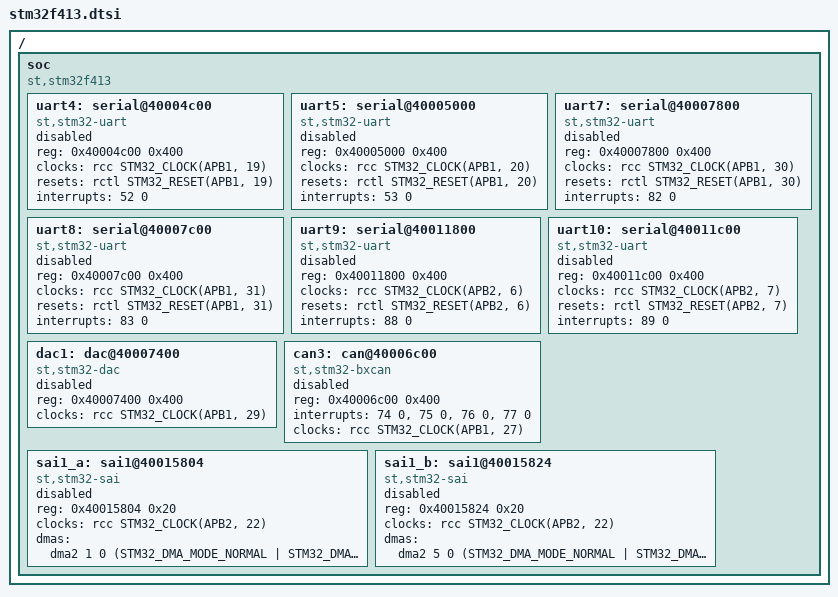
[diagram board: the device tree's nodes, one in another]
/*
 * Copyright (c) 2017 Florian Vaussard, HEIG-VD
 * Copyright (c) 2025 Mario Paja
 *
 * SPDX-License-Identifier: Apache-2.0
 */

#include <st/f4/stm32f412.dtsi>

/ {
	soc {
		compatible = "st,stm32f413", "st,stm32f4", "simple-bus";

		uart4: serial@40004c00 {
			compatible = "st,stm32-uart";
			reg = <0x40004c00 0x400>;
			clocks = <&rcc STM32_CLOCK(APB1, 19)>;
			resets = <&rctl STM32_RESET(APB1, 19)>;
			interrupts = <52 0>;
			status = "disabled";
		};

		uart5: serial@40005000 {
			compatible = "st,stm32-uart";
			reg = <0x40005000 0x400>;
			clocks = <&rcc STM32_CLOCK(APB1, 20)>;
			resets = <&rctl STM32_RESET(APB1, 20)>;
			interrupts = <53 0>;
			status = "disabled";
		};

		uart7: serial@40007800 {
			compatible = "st,stm32-uart";
			reg = <0x40007800 0x400>;
			clocks = <&rcc STM32_CLOCK(APB1, 30)>;
			resets = <&rctl STM32_RESET(APB1, 30)>;
			interrupts = <82 0>;
			status = "disabled";
		};

		uart8: serial@40007c00 {
			compatible = "st,stm32-uart";
			reg = <0x40007c00 0x400>;
			clocks = <&rcc STM32_CLOCK(APB1, 31)>;
			resets = <&rctl STM32_RESET(APB1, 31)>;
			interrupts = <83 0>;
			status = "disabled";
		};

		uart9: serial@40011800 {
			compatible = "st,stm32-uart";
			reg = <0x40011800 0x400>;
			clocks = <&rcc STM32_CLOCK(APB2, 6)>;
			resets = <&rctl STM32_RESET(APB2, 6)>;
			interrupts = <88 0>;
			status = "disabled";
		};

		uart10: serial@40011c00 {
			compatible = "st,stm32-uart";
			reg = <0x40011c00 0x400>;
			clocks = <&rcc STM32_CLOCK(APB2, 7)>;
			resets = <&rctl STM32_RESET(APB2, 7)>;
			interrupts = <89 0>;
			status = "disabled";
		};

		dac1: dac@40007400 {
			compatible = "st,stm32-dac";
			reg = <0x40007400 0x400>;
			clocks = <&rcc STM32_CLOCK(APB1, 29)>;
			status = "disabled";
			#io-channel-cells = <1>;
		};

		can3: can@40006c00 {
			compatible = "st,stm32-bxcan";
			reg = <0x40006c00 0x400>;
			interrupts = <74 0>, <75 0>, <76 0>, <77 0>;
			interrupt-names = "TX", "RX0", "RX1", "SCE";
			clocks = <&rcc STM32_CLOCK(APB1, 27)>;
			status = "disabled";
		};

		sai1_a: sai1@40015804 {
			compatible = "st,stm32-sai";
			#address-cells = <1>;
			#size-cells = <0>;
			reg = <0x40015804 0x20>;
			clocks = <&rcc STM32_CLOCK(APB2, 22)>;
			dmas = <&dma2 1 0 (STM32_DMA_MODE_NORMAL | STM32_DMA_PRIORITY_HIGH |
					   STM32_DMA_16BITS) 0>;
			status = "disabled";
		};

		sai1_b: sai1@40015824 {
			compatible = "st,stm32-sai";
			#address-cells = <1>;
			#size-cells = <0>;
			reg = <0x40015824 0x20>;
			clocks = <&rcc STM32_CLOCK(APB2, 22)>;
			dmas = <&dma2 5 0 (STM32_DMA_MODE_NORMAL | STM32_DMA_PRIORITY_HIGH |
					   STM32_DMA_16BITS) 0>;
			status = "disabled";
		};
	};
};
